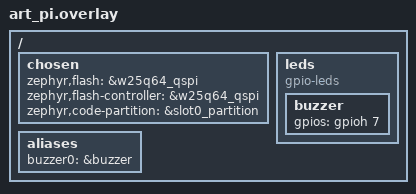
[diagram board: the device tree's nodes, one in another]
/*
 * Copyright (c) 2025 STMicroelectronics
 *
 * SPDX-License-Identifier: Apache-2.0
 */

/*
 * Define the device, controller and partition to be the external memory
 * for running the application in external NOR from MCUboot
 */
// #include <zephyr/dt-bindings/gpio/gpio.h>

/ {
	chosen {
		zephyr,flash = &w25q64_qspi;
		zephyr,flash-controller = &w25q64_qspi;
		zephyr,code-partition = &slot0_partition;
	};	
};


/ {
    leds {
        compatible = "gpio-leds";
        status = "okay";

        buzzer: buzzer {
            gpios = <&gpioh 7 GPIO_ACTIVE_HIGH>;
            /* 可选：label = "BUZZER"; function = "buzzer"; */
        };
    };

    aliases {
        buzzer0 = &buzzer;
    };
};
